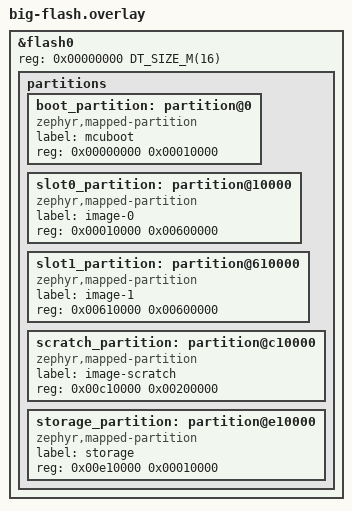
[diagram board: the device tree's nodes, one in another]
/* A simulated flash large enough for a host executable to be an MCUboot image: native_sim's
 * slots are 420 KB each, a native_sim executable is a few MB. The flash simulator's size is
 * whatever the devicetree says, and its file is sparse. */
/delete-node/ &slot0_partition;
/delete-node/ &slot1_partition;
/delete-node/ &scratch_partition;
/delete-node/ &storage_partition;
/delete-node/ &boot_partition;

&flash0 {
	reg = <0x00000000 DT_SIZE_M(16)>;
	partitions {
		boot_partition: partition@0 {
			compatible = "zephyr,mapped-partition";
			label = "mcuboot";
			reg = <0x00000000 0x00010000>;
		};
		slot0_partition: partition@10000 {
			compatible = "zephyr,mapped-partition";
			label = "image-0";
			reg = <0x00010000 0x00600000>;
		};
		slot1_partition: partition@610000 {
			compatible = "zephyr,mapped-partition";
			label = "image-1";
			reg = <0x00610000 0x00600000>;
		};
		scratch_partition: partition@c10000 {
			compatible = "zephyr,mapped-partition";
			label = "image-scratch";
			reg = <0x00c10000 0x00200000>;
		};
		storage_partition: partition@e10000 {
			compatible = "zephyr,mapped-partition";
			label = "storage";
			reg = <0x00e10000 0x00010000>;
		};
	};
};
